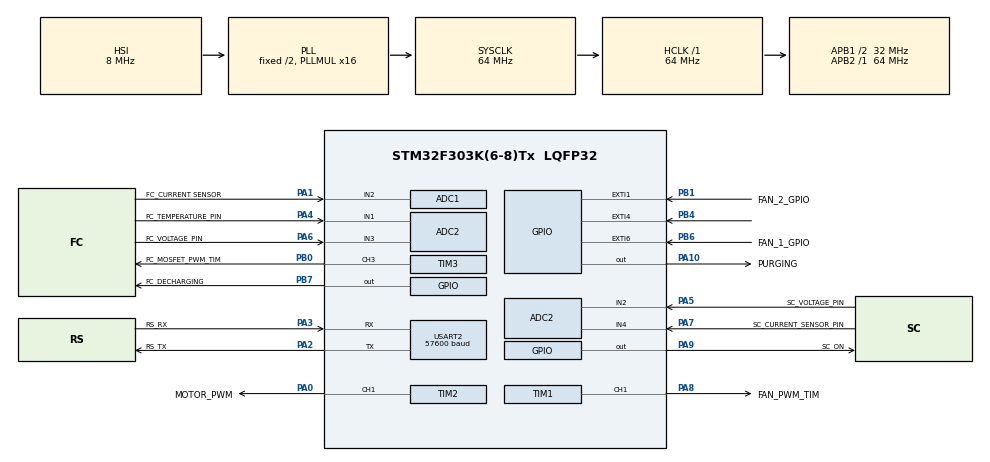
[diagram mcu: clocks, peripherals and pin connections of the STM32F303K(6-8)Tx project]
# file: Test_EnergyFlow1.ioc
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ADC1.Channel-0\#ChannelRegularConversion=ADC_CHANNEL_2
ADC1.NbrOfConversionFlag=1
ADC1.Offset-0\#ChannelRegularConversion=0
ADC1.OffsetNumber-0\#ChannelRegularConversion=ADC_OFFSET_NONE
ADC1.Rank-0\#ChannelRegularConversion=1
ADC1.SamplingTime-0\#ChannelRegularConversion=ADC_SAMPLETIME_181CYCLES_5
ADC1.SamplingTimeOPAMP-0\#ChannelRegularConversion=ADC_SAMPLETIME_61CYCLES_5
ADC1.SubFamily=STM32F303x8
ADC1.master=1
ADC2.Channel-0\#ChannelRegularConversion=ADC_CHANNEL_1
ADC2.Channel-7\#ChannelRegularConversion=ADC_CHANNEL_2
ADC2.Channel-8\#ChannelRegularConversion=ADC_CHANNEL_3
ADC2.Channel-9\#ChannelRegularConversion=ADC_CHANNEL_4
ADC2.ClockPrescaler=ADC_CLOCK_ASYNC_DIV1
ADC2.ContinuousConvMode=ENABLE
ADC2.DMAContinuousRequests=ENABLE
ADC2.EOCSelection=ADC_EOC_SINGLE_CONV
ADC2.EnableInjectedConversion=DISABLE
ADC2.NbrOfConversion=4
ADC2.NbrOfConversionFlag=1
ADC2.Offset-0\#ChannelRegularConversion=0
ADC2.Offset-7\#ChannelRegularConversion=0
ADC2.Offset-8\#ChannelRegularConversion=0
ADC2.Offset-9\#ChannelRegularConversion=0
ADC2.OffsetNumber-0\#ChannelRegularConversion=ADC_OFFSET_NONE
ADC2.OffsetNumber-7\#ChannelRegularConversion=ADC_OFFSET_NONE
ADC2.OffsetNumber-8\#ChannelRegularConversion=ADC_OFFSET_NONE
ADC2.OffsetNumber-9\#ChannelRegularConversion=ADC_OFFSET_NONE
ADC2.Rank-0\#ChannelRegularConversion=1
ADC2.Rank-7\#ChannelRegularConversion=2
ADC2.Rank-8\#ChannelRegularConversion=3
ADC2.Rank-9\#ChannelRegularConversion=4
ADC2.SamplingTime-0\#ChannelRegularConversion=ADC_SAMPLETIME_601CYCLES_5
ADC2.SamplingTime-7\#ChannelRegularConversion=ADC_SAMPLETIME_601CYCLES_5
ADC2.SamplingTime-8\#ChannelRegularConversion=ADC_SAMPLETIME_601CYCLES_5
ADC2.SamplingTime-9\#ChannelRegularConversion=ADC_SAMPLETIME_601CYCLES_5
ADC2.SequencerNbRanks=1
ADC2.SubFamily=STM32F303x8
CRC.CRCLength=CRC_POLYLENGTH_8B
CRC.DefaultInitValueUse=DEFAULT_INIT_VALUE_ENABLE
CRC.DefaultPolynomialUse=DEFAULT_POLYNOMIAL_DISABLE
Dma.ADC2.1.Direction=DMA_PERIPH_TO_MEMORY
Dma.ADC2.1.Instance=DMA1_Channel4
Dma.ADC2.1.MemDataAlignment=DMA_MDATAALIGN_HALFWORD
Dma.ADC2.1.MemInc=DMA_MINC_ENABLE
Dma.ADC2.1.Mode=DMA_CIRCULAR
Dma.ADC2.1.PeriphDataAlignment=DMA_PDATAALIGN_HALFWORD
Dma.ADC2.1.PeriphInc=DMA_PINC_DISABLE
Dma.ADC2.1.Priority=DMA_PRIORITY_LOW
Dma.Request0=USART2_RX
Dma.Request1=ADC2
Dma.Request2=TIM1_CH1
Dma.Request3=TIM2_CH1
Dma.TIM1_CH1.2.Direction=DMA_MEMORY_TO_PERIPH
Dma.TIM1_CH1.2.Instance=DMA1_Channel2
Dma.TIM1_CH1.2.MemDataAlignment=DMA_MDATAALIGN_HALFWORD
Dma.TIM1_CH1.2.MemInc=DMA_MINC_ENABLE
Dma.TIM1_CH1.2.Mode=DMA_CIRCULAR
Dma.TIM1_CH1.2.PeriphDataAlignment=DMA_PDATAALIGN_HALFWORD
Dma.TIM1_CH1.2.PeriphInc=DMA_PINC_DISABLE
Dma.TIM1_CH1.2.Priority=DMA_PRIORITY_LOW
Dma.TIM2_CH1.3.Direction=DMA_MEMORY_TO_PERIPH
Dma.TIM2_CH1.3.Instance=DMA1_Channel5
Dma.TIM2_CH1.3.MemDataAlignment=DMA_MDATAALIGN_WORD
Dma.TIM2_CH1.3.MemInc=DMA_MINC_ENABLE
Dma.TIM2_CH1.3.Mode=DMA_CIRCULAR
Dma.TIM2_CH1.3.PeriphDataAlignment=DMA_PDATAALIGN_WORD
Dma.TIM2_CH1.3.PeriphInc=DMA_PINC_DISABLE
Dma.TIM2_CH1.3.Priority=DMA_PRIORITY_LOW
Dma.USART2_RX.0.Direction=DMA_PERIPH_TO_MEMORY
Dma.USART2_RX.0.Instance=DMA1_Channel6
Dma.USART2_RX.0.MemDataAlignment=DMA_MDATAALIGN_BYTE
Dma.USART2_RX.0.MemInc=DMA_MINC_ENABLE
Dma.USART2_RX.0.Mode=DMA_NORMAL
Dma.USART2_RX.0.PeriphDataAlignment=DMA_PDATAALIGN_BYTE
Dma.USART2_RX.0.PeriphInc=DMA_PINC_DISABLE
Dma.USART2_RX.0.Priority=DMA_PRIORITY_HIGH
IWDG.Reload=1500
IWDG.Window=2000
Mcu.Family=STM32F3
Mcu.Name=STM32F303K(6-8)Tx
Mcu.Package=LQFP32
NVIC.DMA1_Channel2_IRQn=true\:0\:0\:false\:false\:true\:false\:true\:true
NVIC.DMA1_Channel4_IRQn=true\:0\:0\:false\:false\:true\:false\:true\:true
NVIC.DMA1_Channel5_IRQn=true\:0\:0\:false\:false\:true\:false\:true\:true
NVIC.DMA1_Channel6_IRQn=true\:0\:0\:false\:false\:true\:false\:true\:true
NVIC.EXTI1_IRQn=true\:3\:0\:true\:false\:true\:true\:true\:true
NVIC.EXTI4_IRQn=true\:3\:0\:true\:false\:true\:true\:true\:true
NVIC.EXTI9_5_IRQn=true\:1\:0\:true\:false\:true\:true\:true\:true
NVIC.PriorityGroup=NVIC_PRIORITYGROUP_4
NVIC.TIM6_DAC1_IRQn=true\:1\:0\:true\:false\:true\:true\:true\:true
NVIC.TIM7_DAC2_IRQn=true\:3\:0\:true\:false\:true\:true\:true\:true
NVIC.USART2_IRQn=true\:1\:0\:true\:false\:true\:true\:true\:true
PA0.GPIO_Label=MOTOR_PWM
PA0.Signal=S_TIM2_CH1_ETR
PA1.GPIO_Label=FC_CURRENT SENSOR
PA1.Mode=IN2-Single-Ended
PA1.Signal=ADC1_IN2
PA10.GPIO_Label=PURGING
PA10.GPIO_PuPd=GPIO_PULLDOWN
PA10.Signal=GPIO_Output
PA13.GPIO_Label=SWDIO
PA13.Signal=SYS_JTMS-SWDIO
PA14.GPIO_Label=SWCLK
PA14.Signal=SYS_JTCK-SWCLK
PA2.GPIO_Label=RS_TX
PA2.Mode=Asynchronous
PA2.Signal=USART2_TX
PA3.GPIO_Label=RS_RX
PA3.Mode=Asynchronous
PA3.Signal=USART2_RX
PA4.GPIO_Label=FC_TEMPERATURE_PIN
PA4.Mode=IN1-Single-Ended
PA4.Signal=ADC2_IN1
PA5.GPIO_Label=SC_VOLTAGE_PIN
PA5.Mode=IN2-Single-Ended
PA5.Signal=ADC2_IN2
PA6.GPIO_Label=FC_VOLTAGE_PIN
PA6.Mode=IN3-Single-Ended
PA6.Signal=ADC2_IN3
PA7.GPIO_Label=SC_CURRENT_SENSOR_PIN
PA7.Mode=IN4-Single-Ended
PA7.Signal=ADC2_IN4
PA8.GPIO_Label=FAN_PWM_TIM
PA8.Signal=S_TIM1_CH1
PA9.GPIO_Label=SC_ON
PA9.Signal=GPIO_Output
PB0.GPIO_Label=FC_MOSFET_PWM_TIM
PB0.Signal=S_TIM3_CH3
PB1.GPIO_Label=FAN_2_GPIO
PB1.GPIO_ModeDefaultEXTI=GPIO_MODE_IT_FALLING
PB1.GPIO_PuPd=GPIO_NOPULL
PB1.Signal=GPXTI1
PB4.GPIO_ModeDefaultEXTI=GPIO_MODE_IT_FALLING
PB4.Signal=GPXTI4
PB6.GPIO_Label=FAN_1_GPIO
PB6.GPIO_ModeDefaultEXTI=GPIO_MODE_IT_FALLING
PB6.GPIO_PuPd=GPIO_NOPULL
PB6.Signal=GPXTI6
PB7.GPIO_Label=FC_DECHARGING
PB7.Signal=GPIO_Output
PF0\ /\ OSC_IN.GPIO_Label=MCO
PF0\ /\ OSC_IN.Signal=RCC_OSC_IN
ProjectManager.HeapSize=0x200
ProjectManager.StackSize=0x400
ProjectManager.TargetToolchain=STM32CubeIDE
RCC.AHBFreq_Value=64000000
RCC.APB1CLKDivider=RCC_HCLK_DIV2
RCC.APB1Freq_Value=32000000
RCC.APB1TimFreq_Value=64000000
RCC.APB2Freq_Value=64000000
RCC.APB2TimFreq_Value=64000000
RCC.CortexFreq_Value=64000000
RCC.HCLKFreq_Value=64000000
RCC.HSE_VALUE=8000000
RCC.HSI_VALUE=8000000
RCC.PLLMUL=RCC_PLL_MUL16
RCC.SYSCLKFreq_VALUE=64000000
RCC.SYSCLKSourceVirtual=RCC_SYSCLKSOURCE_PLLCLK
SH.S_TIM1_CH1.0=TIM1_CH1,PWM Generation1 CH1
SH.S_TIM2_CH1_ETR.0=TIM2_CH1,PWM Generation1 CH1
SH.S_TIM3_CH3.0=TIM3_CH3,PWM Generation3 CH3
TIM1.Channel-PWM\ Generation1\ CH1=TIM_CHANNEL_1
TIM1.Channel-PWM\ Generation4\ CH4=TIM_CHANNEL_4
TIM1.Period=255
TIM1.Prescaler=9
TIM2.Channel-PWM\ Generation1\ CH1=TIM_CHANNEL_1
TIM2.Channel-PWM\ Generation2\ CH2=TIM_CHANNEL_2
TIM2.Period=240
TIM2.Prescaler=9
TIM3.Channel-PWM\ Generation2\ CH2=TIM_CHANNEL_2
TIM3.Channel-PWM\ Generation3\ CH3=TIM_CHANNEL_3
TIM3.Period=99
TIM3.Prescaler=1199
TIM6.Period=100-1
TIM6.Prescaler=64-1
TIM7.AutoReloadPreload=TIM_AUTORELOAD_PRELOAD_ENABLE
TIM7.Period=10-1
TIM7.Prescaler=64-1
USART2.BaudRate=57600
USART2.DMADisableonRxErrorParam=ADVFEATURE_DMA_DISABLEONRXERROR
USART2.OneBitSampling=UART_ONE_BIT_SAMPLE_ENABLE
USART2.OverSampling=UART_OVERSAMPLING_8
USART2.OverrunDisableParam=ADVFEATURE_OVERRUN_DISABLE
USART2.VirtualMode-Asynchronous=VM_ASYNC
VP_CRC_VS_CRC.Mode=CRC_Activate
VP_IWDG_VS_IWDG.Mode=IWDG_Activate
VP_TIM1_VS_ClockSourceINT.Mode=Internal
VP_TIM2_VS_ClockSourceINT.Mode=Internal
VP_TIM3_VS_ClockSourceINT.Mode=Internal
VP_TIM6_VS_ClockSourceINT.Mode=Enable_Timer
VP_TIM7_VS_ClockSourceINT.Mode=Enable_Timer
board=NUCLEO-F303K8

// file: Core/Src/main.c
/* USER CODE BEGIN Header */
/**
 ******************************************************************************
 * @file           : main.c
 * @brief          : Main program body
 ******************************************************************************
 * @attention
 *
 * <h2><center>&copy; Copyright (c) 2020 STMicroelectronics.
 * All rights reserved.</center></h2>
 *
 * This software component is licensed by ST under BSD 3-Clause license,
 * the "License"; You may not use this file except in compliance with the
 * License. You may obtain a copy of the License at:
 *                        opensource.org/licenses/BSD-3-Clause
 *
 ******************************************************************************
 */
/* USER CODE END Header */
#include "main.h"
#include "adc.h"
#include "crc.h"
#include "dma.h"
#include "iwdg.h"
#include "tim.h"
#include "usart.h"
#include "gpio.h"

/* USER CODE BEGIN Includes */
#include "../../Hydrogreen/hydrogreen.h"

/* USER CODE END Includes */

void SystemClock_Config(void);
/* USER CODE BEGIN PFP */
void HAL_SYSTICK_Callback();
void ADC_SetActiveChannel(ADC_HandleTypeDef *hadc, uint32_t AdcChannel);
void HAL_UART_RxCpltCallback(UART_HandleTypeDef *huart);
/* USER CODE END PFP */

/* USER CODE BEGIN 0 */
void HAL_UART_RxCpltCallback(UART_HandleTypeDef *huart);
void HAL_SYSTICK_Callback();

/* USER CODE END 0 */

int main(void)
{

  /* MCU Configuration--------------------------------------------------------*/

  /* Reset of all peripherals, Initializes the Flash interface and the Systick. */
  HAL_Init();

  /* Configure the system clock */
  SystemClock_Config();

  /* Initialize all configured peripherals */
  MX_GPIO_Init();
  MX_DMA_Init();
  MX_USART2_UART_Init();
  MX_ADC2_Init();
  MX_TIM1_Init();
  MX_TIM2_Init();
  MX_TIM3_Init();
  MX_CRC_Init();
  MX_IWDG_Init();
  MX_TIM6_Init();
  MX_TIM7_Init();
  MX_ADC1_Init();
  /* USER CODE BEGIN 2 */
  hydrogreen_main();
  /* USER CODE END 2 */

  /* Infinite loop */
  while (1)
    {

    }
}

void SystemClock_Config(void)
{
  RCC_OscInitTypeDef RCC_OscInitStruct = {0};
  RCC_ClkInitTypeDef RCC_ClkInitStruct = {0};
  RCC_PeriphCLKInitTypeDef PeriphClkInit = {0};

  /** Initializes the RCC Oscillators according to the specified parameters
  * in the RCC_OscInitTypeDef structure.
  */
  RCC_OscInitStruct.OscillatorType = RCC_OSCILLATORTYPE_HSI|RCC_OSCILLATORTYPE_LSI;
  RCC_OscInitStruct.HSIState = RCC_HSI_ON;
  RCC_OscInitStruct.HSICalibrationValue = RCC_HSICALIBRATION_DEFAULT;
  RCC_OscInitStruct.LSIState = RCC_LSI_ON;
  RCC_OscInitStruct.PLL.PLLState = RCC_PLL_ON;
  RCC_OscInitStruct.PLL.PLLSource = RCC_PLLSOURCE_HSI;
  RCC_OscInitStruct.PLL.PLLMUL = RCC_PLL_MUL16;
  if (HAL_RCC_OscConfig(&RCC_OscInitStruct) != HAL_OK)
  {
    Error_Handler();
  }
  /** Initializes the CPU, AHB and APB buses clocks
  */
  RCC_ClkInitStruct.ClockType = RCC_CLOCKTYPE_HCLK|RCC_CLOCKTYPE_SYSCLK
                              |RCC_CLOCKTYPE_PCLK1|RCC_CLOCKTYPE_PCLK2;
  RCC_ClkInitStruct.SYSCLKSource = RCC_SYSCLKSOURCE_PLLCLK;
  RCC_ClkInitStruct.AHBCLKDivider = RCC_SYSCLK_DIV1;
  RCC_ClkInitStruct.APB1CLKDivider = RCC_HCLK_DIV2;
  RCC_ClkInitStruct.APB2CLKDivider = RCC_HCLK_DIV1;

  if (HAL_RCC_ClockConfig(&RCC_ClkInitStruct, FLASH_LATENCY_2) != HAL_OK)
  {
    Error_Handler();
  }
  PeriphClkInit.PeriphClockSelection = RCC_PERIPHCLK_TIM1|RCC_PERIPHCLK_ADC12;
  PeriphClkInit.Adc12ClockSelection = RCC_ADC12PLLCLK_DIV1;
  PeriphClkInit.Tim1ClockSelection = RCC_TIM1CLK_HCLK;
  if (HAL_RCCEx_PeriphCLKConfig(&PeriphClkInit) != HAL_OK)
  {
    Error_Handler();
  }
}

void Error_Handler(void)
{
  /* USER CODE BEGIN Error_Handler_Debug */
  /* User can add his own implementation to report the HAL error return state */
  hydrogreen_hardFault();
  /* USER CODE END Error_Handler_Debug */
}

/************************ (C) COPYRIGHT STMicroelectronics *****END OF FILE****/
